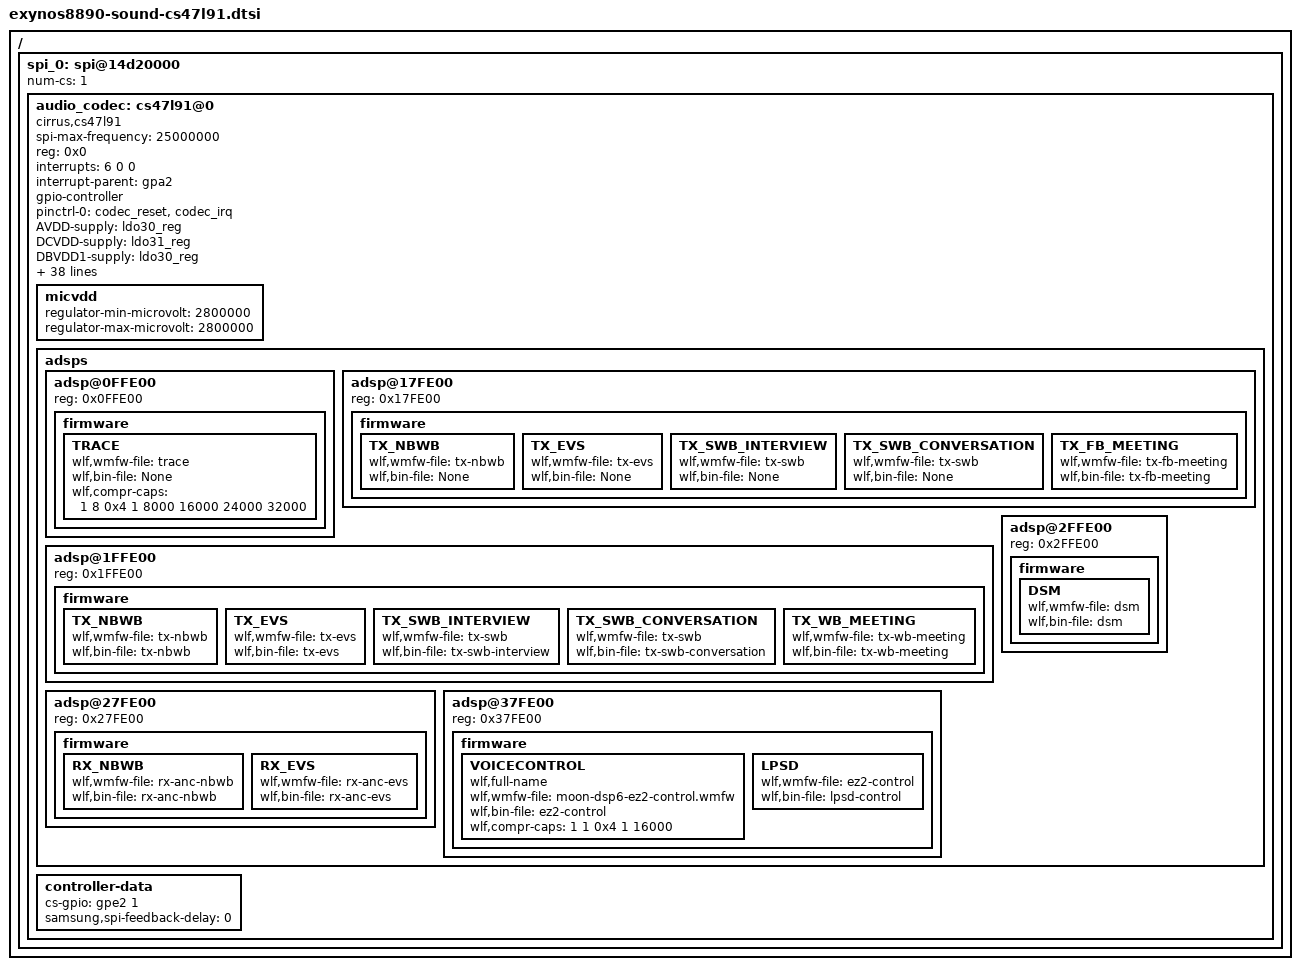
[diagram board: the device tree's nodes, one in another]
/*
 * SAMSUNG Lucky-CS47L91 Sound Card Device Tree Source
 *
 * Copyright (c) 2015 Samsung Electronics Co., Ltd.
 *		http://www.samsung.com
 *
 * This program is free software; you can redistribute it and/or modify
 * it under the terms of the GNU General Public License version 2 as
 * published by the Free Software Foundation.
*/

/ {
	spi_0: spi@14d20000 {
		/delete-property/ dma-mode;
		/delete-property/ dmas;
		/delete-property/ dma-names;

		num-cs = <1>;
		status = "okay";

		audio_codec: cs47l91@0 {
			spi-max-frequency = <25000000>;
			compatible = "cirrus,cs47l91";
			reg = <0x0>;
			interrupts = <6 0 0>;
			interrupt-parent = <&gpa2>;
			gpio-controller;
			#gpio-cells = <2>;

			pinctrl-names ="default";
			pinctrl-0 = <&codec_reset &codec_irq>;

			AVDD-supply = <&ldo30_reg>;
			DCVDD-supply = <&ldo31_reg>;
			DBVDD1-supply = <&ldo30_reg>;
			DBVDD2-supply = <&ldo30_reg>;
			DBVDD3-supply = <&ldo30_reg>;
			DBVDD4-supply = <&ldo30_reg>;
			CPVDD-supply = <&ldo30_reg>;
			SPKVDDL-supply = <&ldo30_reg>;
			SPKVDDR-supply = <&ldo30_reg>;

			wlf,reset = <&gpe6 5 0>;
			wlf,init-mic-delay = <30>;
			wlf,micd-clamp-mode = <0x8>;
			wlf,use-jd-gpio;
			wlf,micd-detect-debounce = <300>;
			wlf,micd-pol-gpio = <0>;
			wlf,micd-bias-start-time = <0x1>;
			wlf,gpsw = <0x3>;
			wlf,micd-rate = <0x7>;
			wlf,micd-dbtime = <0x1>;
			wlf,micd-timeout = <1000>;
			wlf,micd-force-micbias;
			wlf,hs-mic = <3>;
			wlf,hpdet-moisture-imp = <2000>;
			wlf,hpdet-moisture-debounce = <40>;
			wlf,hpdet-ext-res = <34>;

			wlf,hpdet-short-circuit-imp = <2>;
			wlf,micd-ranges = <
				116 226
				173 582
				321 115
				752 114
				1257 217
			>;

			wlf,micd-software-compare;
			wlf,micd-open-circuit-declare = <1>;
			wlf,jd-wake-time = <5000>;

			wlf,max-channels-clocked = <2 0 0 0>;

			wlf,micd-configs = <
				0 1 0 0 /*MICDET1|MICDET2/HPOUTFB2|MICBIAS1A|micd-poll-gpio pin= NONE*/
			>;
			wlf,hpd-left-pins = <0 5>; /*CLAMP : HPOUT1L, SENSE: HPDET2*/

			wlf,micbias1 = <2800 0 1 1 1 1 1 0>;
			wlf,micbias2 = <1800 0 1 1 1 1 1 0>;

			/* 0:MICVDD 1:MICBIAS1 2:MICBIAS2 3:MICBIAS3 */
			wlf,dmic-ref = <2 1 2 0 0>;
			/* 1st cell:IN1L 2rd cell:IN1R 3nd cell:IN2L 4th cell:IN2R... 10th cell:IN5R */
			wlf,inmode = <2 2 0 0 2 2 0 0 0 0>;
			/* 1st cell:OUT1 2nd cell:OUT2 3rd cell:OUT3... 6th cell:OUT6 */
			wlf,out-mono = <0 1 1 0 0 0>;

			wlf,gpio-defaults = <
				0xffffffff 0xffffffff /* GPIO1 */
				0xffffffff 0xffffffff /* GPIO2 */
				0xffffffff 0xffffffff /* GPIO3 */
				0xffffffff 0xffffffff /* GPIO4 */
				0xffffffff 0xffffffff /* GPIO5 */
				0xffffffff 0xffffffff /* GPIO6 */
				0xffffffff 0xffffffff /* GPIO7 */
				0xffffffff 0xffffffff /* GPIO8 */
				0xffffffff 0xffffffff /* MIF1SCLK / GPIO9 */
				0xffffffff 0xffffffff /* MIF1SDA / GPIO10 */
				0xffffffff 0xffffffff /* MIF2SCLK / GPIO11 */
				0xffffffff 0xffffffff /* MIF2SDA / GPIO12 */
				0xffffffff 0xffffffff /* MIF3SCLK / GPIO13 */
				0xffffffff 0xffffffff /* MIF3SDA / GPIO14 */
				0x00002000 0x00006000 /* AIF1TXDAT / GPIO15 */
				0x00002000 0x00006000 /* AIF1BCLK / GPIO16 */
				0x00002000 0x00006000 /* AIF1RXDAT / GPIO17 */
				0x00002000 0x00006000 /* AIF1LRCLK / GPIO18 */
				0x00002000 0x00006000 /* AIF2TXDAT / GPIO19 */
				0x00002000 0x00006000 /* AIF2BCLK / GPIO20 */
				0x00002000 0x00006000 /* AIF2RXDAT / GPIO21 */
				0x00002000 0x00006000 /* AIF2LRCLK / GPIO22 */
				0x00002000 0x00006000 /* AIF3TXDAT / GPIO23 */
				0x00002000 0x00006000 /* AIF3BCLK / GPIO24 */
				0x00002000 0x00006000 /* AIF3RXDAT / GPIO25 */
				0x00002000 0x00006000 /* AIF3LRCLK / GPIO26 */
				0x00002000 0x00006000 /* AIF4TXDAT / GPIO27 */
				0x00002000 0x00006000 /* AIF4BCLK / GPIO28 */
				0x00002000 0x00006000 /* AIF4RXDAT / GPIO29 */
				0x00002000 0x00006000 /* AIF4LRCLK / GPIO30 */
				0x00002000 0x00006000 /* DMICCLK4 / GPIO31 */
				0x00002000 0x00006000 /* DMICDAT4 / GPIO32 */
				0x00002000 0x00006000 /* DMICCLK5 / GPIO33 */
				0x00002000 0x00006000 /* DMICDAT5 / GPIO34 */
				0x00002000 0x00006000 /* DMICCLK6 / GPIO35 */
				0x00002000 0x00006000 /* DMICDAT6 / GPIO36 */
				0x00002000 0x00006000 /* SPKCLK1 / GPIO37 */
				0x00002000 0x00006000 /* SPKCLK2 / GPIO38 */
			>;

			micvdd {
			       regulator-min-microvolt = <2800000>;
			       regulator-max-microvolt = <2800000>;
			};

			adsps {
				#address-cells = <1>;
				#size-cells = <0>;

				adsp@0FFE00 {
					reg = <0x0FFE00>;
					firmware {
						TRACE {
							wlf,wmfw-file = "trace";
							wlf,bin-file = "None";
							wlf,compr-caps = <1 8 0x4 1 8000 16000 24000 32000>;
						};
					};
				};
				adsp@17FE00 {
					reg = <0x17FE00>;
					firmware {
						TX_NBWB {
							wlf,wmfw-file = "tx-nbwb";
							wlf,bin-file = "None";
						};
						TX_EVS {
							wlf,wmfw-file = "tx-evs";
							wlf,bin-file = "None";
						};
						TX_SWB_INTERVIEW {
							wlf,wmfw-file = "tx-swb";
							wlf,bin-file = "None";
						};
						TX_SWB_CONVERSATION {
							wlf,wmfw-file = "tx-swb";
							wlf,bin-file = "None";
						};
						TX_FB_MEETING {
							wlf,wmfw-file = "tx-fb-meeting";
							wlf,bin-file = "tx-fb-meeting";
						};
					};
				};
				adsp@1FFE00 {
					reg = <0x1FFE00>;
					firmware {
						TX_NBWB {
							wlf,wmfw-file = "tx-nbwb";
							wlf,bin-file = "tx-nbwb";
						};
						TX_EVS {
							wlf,wmfw-file = "tx-evs";
							wlf,bin-file = "tx-evs";
						};
						TX_SWB_INTERVIEW {
							wlf,wmfw-file = "tx-swb";
							wlf,bin-file = "tx-swb-interview";
						};
						TX_SWB_CONVERSATION {
							wlf,wmfw-file = "tx-swb";
							wlf,bin-file = "tx-swb-conversation";
						};
						TX_WB_MEETING {
							wlf,wmfw-file = "tx-wb-meeting";
							wlf,bin-file = "tx-wb-meeting";
						};
					};
				};
				adsp@27FE00 {
					reg = <0x27FE00>;
					firmware {
						RX_NBWB {
							wlf,wmfw-file = "rx-anc-nbwb";
							wlf,bin-file = "rx-anc-nbwb";
						};
						RX_EVS {
							wlf,wmfw-file = "rx-anc-evs";
							wlf,bin-file = "rx-anc-evs";
						};
					};
				};
				adsp@37FE00 {
					reg = <0x37FE00>;
					firmware {
						VOICECONTROL {
							wlf,full-name;
							wlf,wmfw-file = "moon-dsp6-ez2-control.wmfw";
							wlf,bin-file = "ez2-control";
							wlf,compr-caps = <1 1 0x4 1 16000>;
						};
						LPSD {
							wlf,wmfw-file = "ez2-control";
							wlf,bin-file = "lpsd-control";
						};
					};
				};
				adsp@2FFE00 {
					reg = <0x2FFE00>;
					firmware {
						DSM {
							wlf,wmfw-file = "dsm";
							wlf,bin-file = "dsm";
						};
					};
				};
			};
			controller-data {
				cs-gpio = <&gpe2 1 0>;
				samsung,spi-feedback-delay = <0>;
			};
		};
	};

};
